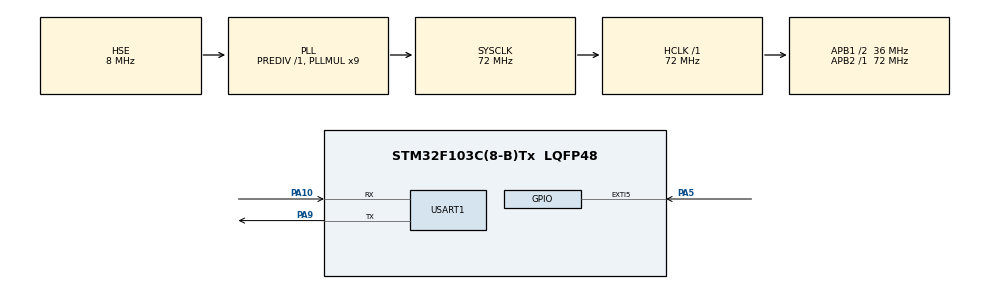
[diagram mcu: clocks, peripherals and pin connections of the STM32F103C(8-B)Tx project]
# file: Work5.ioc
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Mcu.Family=STM32F1
Mcu.Name=STM32F103C(8-B)Tx
Mcu.Package=LQFP48
NVIC.EXTI9_5_IRQn=true\:0\:0\:false\:false\:true\:true\:true\:true
NVIC.PriorityGroup=NVIC_PRIORITYGROUP_4
NVIC.USART1_IRQn=true\:1\:0\:true\:false\:true\:true\:true\:true
PA10.Mode=Asynchronous
PA10.Signal=USART1_RX
PA13.Mode=Serial_Wire
PA13.Signal=SYS_JTMS-SWDIO
PA14.Mode=Serial_Wire
PA14.Signal=SYS_JTCK-SWCLK
PA5.GPIO_ModeDefaultEXTI=GPIO_MODE_IT_RISING
PA5.GPIO_PuPd=GPIO_PULLDOWN
PA5.Signal=GPXTI5
PA9.Mode=Asynchronous
PA9.Signal=USART1_TX
PD0-OSC_IN.Mode=HSE-External-Oscillator
PD0-OSC_IN.Signal=RCC_OSC_IN
PD1-OSC_OUT.Mode=HSE-External-Oscillator
PD1-OSC_OUT.Signal=RCC_OSC_OUT
ProjectManager.HeapSize=0x200
ProjectManager.StackSize=0x400
ProjectManager.TargetToolchain=MDK-ARM V5.32
RCC.AHBFreq_Value=72000000
RCC.APB1CLKDivider=RCC_HCLK_DIV2
RCC.APB1Freq_Value=36000000
RCC.APB1TimFreq_Value=72000000
RCC.APB2Freq_Value=72000000
RCC.APB2TimFreq_Value=72000000
RCC.HCLKFreq_Value=72000000
RCC.PLLMUL=RCC_PLL_MUL9
RCC.PLLSourceVirtual=RCC_PLLSOURCE_HSE
RCC.SYSCLKFreq_VALUE=72000000
RCC.SYSCLKSource=RCC_SYSCLKSOURCE_PLLCLK
RCC.USBFreq_Value=72000000
USART1.VirtualMode=VM_ASYNC
board=custom

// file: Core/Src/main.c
/* USER CODE BEGIN Header */
/**
  ******************************************************************************
  * @file           : main.c
  * @brief          : Main program body
  ******************************************************************************
  * @attention
  *
  * Copyright (c) 2024 STMicroelectronics.
  * All rights reserved.
  *
  * This software is licensed under terms that can be found in the LICENSE file
  * in the root directory of this software component.
  * If no LICENSE file comes with this software, it is provided AS-IS.
  *
  ******************************************************************************
  */
/* USER CODE END Header */
#include "main.h"
#include "usart.h"
#include "gpio.h"

/* USER CODE BEGIN Includes */
#include "stdio.h"
/* USER CODE END Includes */

/* USER CODE BEGIN PV */
#define TIM_DELAY 250                              // 去抖动延迟时间（毫秒）
char Message[] = "clicked\r\n";                   // 中断发生之后发送的字符串数组
volatile uint8_t TxFlag = 0;                      // 数据发送标志位
volatile uint32_t last_time = 0;                 // 记录最后一次中断发生的时间
volatile uint8_t last_state = 0;                 // 记录上一次按键的状态
/* USER CODE END PV */

void SystemClock_Config(void);
/* USER CODE BEGIN PFP */

void Serial_SendByte(uint8_t Byte)
{
      HAL_UART_Transmit(&huart1,&Byte,1,100);     // 使用HAL库发送一个字节的数据
      while(__HAL_UART_GET_FLAG(&huart1,UART_FLAG_TXE) == RESET);   // 等待发送完毕
}

int fputc(int ch , FILE *f)
{
    Serial_SendByte(ch);         // 调用上面定义的函数发送字符
    return ch;                   // 返回发送的字符
}

void HAL_GPIO_EXTI_Callback(uint16_t GPIO_Pin)
{
    if (GPIO_Pin == GPIO_PIN_5)                                     // 检查是否是引脚5的中断
    {
        uint8_t current_state = HAL_GPIO_ReadPin(GPIOA, GPIO_PIN_5); // 读取引脚5的状态
        if (current_state == 1 && last_state == 0)           // 检查当前是否为高电平且上一个状态为低电平
        {
            uint32_t current_time = HAL_GetTick();               // 获取当前系统滴答计数
            if (current_time - last_time > TIM_DELAY) // 检查自上次中断以来是否超过了去抖动时间
            {
                last_time = current_time;             // 更新最后一次中断的时间
                TxFlag = 1;                          // 设置发送消息的标志位
            }
            last_state = 1;                            // 更新为已触发高电平
        }
        else if (current_state == 0 && last_state == 1) // 检查当前是否为低电平且上一个状态为高电平
        {
            last_state = 0;                            // 更新为未触发高电平
        }
    }
}
/* USER CODE END PFP */

int main(void)
{

  /* MCU Configuration--------------------------------------------------------*/

  /* Reset of all peripherals, Initializes the Flash interface and the Systick. */
  HAL_Init();

  /* Configure the system clock */
  SystemClock_Config();

  /* Initialize all configured peripherals */
  MX_GPIO_Init();
  MX_USART1_UART_Init();

  /* Infinite loop */
  while (1)
  {

    /* USER CODE BEGIN 3 */
    if (TxFlag)                 //如果发送标志位为1
    {
        TxFlag = 0;            // 清除发送标志位
        printf("%s",Message);       // 打印消息
    }
  }
  /* USER CODE END 3 */
}

void SystemClock_Config(void)
{
  RCC_OscInitTypeDef RCC_OscInitStruct = {0};
  RCC_ClkInitTypeDef RCC_ClkInitStruct = {0};

  /** Initializes the RCC Oscillators according to the specified parameters
  * in the RCC_OscInitTypeDef structure.
  */
  RCC_OscInitStruct.OscillatorType = RCC_OSCILLATORTYPE_HSE;
  RCC_OscInitStruct.HSEState = RCC_HSE_ON;
  RCC_OscInitStruct.HSEPredivValue = RCC_HSE_PREDIV_DIV1;
  RCC_OscInitStruct.HSIState = RCC_HSI_ON;
  RCC_OscInitStruct.PLL.PLLState = RCC_PLL_ON;
  RCC_OscInitStruct.PLL.PLLSource = RCC_PLLSOURCE_HSE;
  RCC_OscInitStruct.PLL.PLLMUL = RCC_PLL_MUL9;
  if (HAL_RCC_OscConfig(&RCC_OscInitStruct) != HAL_OK)
  {
    Error_Handler();
  }

  /** Initializes the CPU, AHB and APB buses clocks
  */
  RCC_ClkInitStruct.ClockType = RCC_CLOCKTYPE_HCLK|RCC_CLOCKTYPE_SYSCLK
                              |RCC_CLOCKTYPE_PCLK1|RCC_CLOCKTYPE_PCLK2;
  RCC_ClkInitStruct.SYSCLKSource = RCC_SYSCLKSOURCE_PLLCLK;
  RCC_ClkInitStruct.AHBCLKDivider = RCC_SYSCLK_DIV1;
  RCC_ClkInitStruct.APB1CLKDivider = RCC_HCLK_DIV2;
  RCC_ClkInitStruct.APB2CLKDivider = RCC_HCLK_DIV1;

  if (HAL_RCC_ClockConfig(&RCC_ClkInitStruct, FLASH_LATENCY_2) != HAL_OK)
  {
    Error_Handler();
  }
}

void Error_Handler(void)
{
  __disable_irq();
  while (1)
  {
  }
}
